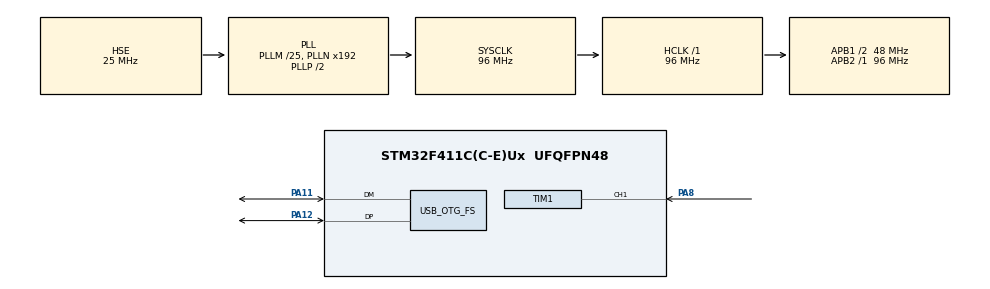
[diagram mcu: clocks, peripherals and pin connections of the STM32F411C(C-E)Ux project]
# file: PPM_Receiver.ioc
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Mcu.Family=STM32F4
Mcu.Name=STM32F411C(C-E)Ux
Mcu.Package=UFQFPN48
NVIC.OTG_FS_IRQn=true\:0\:0\:false\:false\:true\:false\:true\:true
NVIC.PriorityGroup=NVIC_PRIORITYGROUP_4
NVIC.TIM1_CC_IRQn=true\:0\:0\:false\:false\:true\:true\:true\:true
PA11.Mode=Device_Only
PA11.Signal=USB_OTG_FS_DM
PA12.Mode=Device_Only
PA12.Signal=USB_OTG_FS_DP
PA8.Signal=S_TIM1_CH1
PC14-OSC32_IN.Mode=LSE-External-Oscillator
PC14-OSC32_IN.Signal=RCC_OSC32_IN
PC15-OSC32_OUT.Mode=LSE-External-Oscillator
PC15-OSC32_OUT.Signal=RCC_OSC32_OUT
PH0\ -\ OSC_IN.Mode=HSE-External-Oscillator
PH0\ -\ OSC_IN.Signal=RCC_OSC_IN
PH1\ -\ OSC_OUT.Mode=HSE-External-Oscillator
PH1\ -\ OSC_OUT.Signal=RCC_OSC_OUT
ProjectManager.HeapSize=0x200
ProjectManager.StackSize=0x400
ProjectManager.TargetToolchain=Makefile
RCC.48MHZClocksFreq_Value=48000000
RCC.AHBFreq_Value=96000000
RCC.APB1CLKDivider=RCC_HCLK_DIV2
RCC.APB1Freq_Value=48000000
RCC.APB1TimFreq_Value=96000000
RCC.APB2Freq_Value=96000000
RCC.APB2TimFreq_Value=96000000
RCC.CortexFreq_Value=96000000
RCC.HCLKFreq_Value=96000000
RCC.HSE_VALUE=25000000
RCC.HSI_VALUE=16000000
RCC.PLLM=25
RCC.PLLSourceVirtual=RCC_PLLSOURCE_HSE
RCC.SYSCLKFreq_VALUE=96000000
RCC.SYSCLKSource=RCC_SYSCLKSOURCE_PLLCLK
RCC.VCOOutputFreq_Value=192000000
SH.S_TIM1_CH1.0=TIM1_CH1,Input_Capture1_from_TI1
TIM1.Channel-Input_Capture1_from_TI1=TIM_CHANNEL_1
TIM1.ICPolarity_CH1=TIM_INPUTCHANNELPOLARITY_FALLING
TIM1.Prescaler=96 - 1
USB_DEVICE.CLASS_NAME_FS=CDC
USB_DEVICE.VirtualMode=Cdc
USB_DEVICE.VirtualModeFS=Cdc_FS
USB_OTG_FS.VirtualMode=Device_Only
VP_TIM1_VS_ClockSourceINT.Mode=Internal
VP_USB_DEVICE_VS_USB_DEVICE_CDC_FS.Mode=CDC_FS
board=custom

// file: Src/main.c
/* USER CODE BEGIN Header */
/**
  ******************************************************************************
  * @file           : main.c
  * @brief          : Main program body
  ******************************************************************************
  * @attention
  *
  * Copyright (c) 2022 STMicroelectronics.
  * All rights reserved.
  *
  * This software is licensed under terms that can be found in the LICENSE file
  * in the root directory of this software component.
  * If no LICENSE file comes with this software, it is provided AS-IS.
  *
  ******************************************************************************
  */
/* USER CODE END Header */
#include "main.h"
#include "usb_device.h"

/* USER CODE BEGIN Includes */
#include "usbd_cdc_if.h"
#include "FS-IA10B_driver.h"

/* USER CODE END Includes */

TIM_HandleTypeDef htim1;

void SystemClock_Config(void);
static void MX_GPIO_Init(void);
static void MX_TIM1_Init(void);
/* USER CODE BEGIN PFP */
extern uint8_t CDC_Transmit_FS(uint8_t* Buf, uint16_t Len);
extern uint16_t fsia10b_channel_values[];

/* USER CODE END PFP */

/* USER CODE BEGIN 0 */

void HAL_TIM_IC_CaptureCallback(TIM_HandleTypeDef *htim){
    FSIA10B_INT(htim);
}

int _write(int file, char *ptr, int len)
{
    UNUSED(file);
    CDC_Transmit_FS((uint8_t*)ptr, len);
    return len;
}

/* USER CODE END 0 */

int main(void)
{

  /* MCU Configuration--------------------------------------------------------*/

  /* Reset of all peripherals, Initializes the Flash interface and the Systick. */
  HAL_Init();

  /* Configure the system clock */
  SystemClock_Config();

  /* Initialize all configured peripherals */
  MX_GPIO_Init();
  MX_TIM1_Init();
  MX_USB_DEVICE_Init();
  /* USER CODE BEGIN 2 */

  HAL_StatusTypeDef error = HAL_TIM_IC_Start_IT(&htim1, TIM_CHANNEL_1);

  /* USER CODE END 2 */

  /* Infinite loop */
    while (1)
    {

    /* USER CODE BEGIN 3 */
        printf("1 - %4d, 2 - %4d, 3 - %4d, 4 - %4d, 5 - %4d, 6 - %4d, 7 - %4d, 8 - %4d\n",
            fsia10b_channel_values[0], fsia10b_channel_values[1], fsia10b_channel_values[2], fsia10b_channel_values[3],
            fsia10b_channel_values[4], fsia10b_channel_values[5], fsia10b_channel_values[6], fsia10b_channel_values[7]);
        HAL_Delay(500);
    }
  /* USER CODE END 3 */
}

void SystemClock_Config(void)
{
  RCC_OscInitTypeDef RCC_OscInitStruct = {0};
  RCC_ClkInitTypeDef RCC_ClkInitStruct = {0};

  /** Configure the main internal regulator output voltage
  */
  __HAL_RCC_PWR_CLK_ENABLE();
  __HAL_PWR_VOLTAGESCALING_CONFIG(PWR_REGULATOR_VOLTAGE_SCALE1);

  /** Initializes the RCC Oscillators according to the specified parameters
  * in the RCC_OscInitTypeDef structure.
  */
  RCC_OscInitStruct.OscillatorType = RCC_OSCILLATORTYPE_HSE;
  RCC_OscInitStruct.HSEState = RCC_HSE_ON;
  RCC_OscInitStruct.PLL.PLLState = RCC_PLL_ON;
  RCC_OscInitStruct.PLL.PLLSource = RCC_PLLSOURCE_HSE;
  RCC_OscInitStruct.PLL.PLLM = 25;
  RCC_OscInitStruct.PLL.PLLN = 192;
  RCC_OscInitStruct.PLL.PLLP = RCC_PLLP_DIV2;
  RCC_OscInitStruct.PLL.PLLQ = 4;
  if (HAL_RCC_OscConfig(&RCC_OscInitStruct) != HAL_OK)
  {
    Error_Handler();
  }

  /** Initializes the CPU, AHB and APB buses clocks
  */
  RCC_ClkInitStruct.ClockType = RCC_CLOCKTYPE_HCLK|RCC_CLOCKTYPE_SYSCLK
                              |RCC_CLOCKTYPE_PCLK1|RCC_CLOCKTYPE_PCLK2;
  RCC_ClkInitStruct.SYSCLKSource = RCC_SYSCLKSOURCE_PLLCLK;
  RCC_ClkInitStruct.AHBCLKDivider = RCC_SYSCLK_DIV1;
  RCC_ClkInitStruct.APB1CLKDivider = RCC_HCLK_DIV2;
  RCC_ClkInitStruct.APB2CLKDivider = RCC_HCLK_DIV1;

  if (HAL_RCC_ClockConfig(&RCC_ClkInitStruct, FLASH_LATENCY_3) != HAL_OK)
  {
    Error_Handler();
  }
}

static void MX_TIM1_Init(void)
{

  TIM_ClockConfigTypeDef sClockSourceConfig = {0};
  TIM_MasterConfigTypeDef sMasterConfig = {0};
  TIM_IC_InitTypeDef sConfigIC = {0};

  htim1.Instance = TIM1;
  htim1.Init.Prescaler = 96 - 1;
  htim1.Init.CounterMode = TIM_COUNTERMODE_UP;
  htim1.Init.Period = 65535;
  htim1.Init.ClockDivision = TIM_CLOCKDIVISION_DIV1;
  htim1.Init.RepetitionCounter = 0;
  htim1.Init.AutoReloadPreload = TIM_AUTORELOAD_PRELOAD_DISABLE;
  if (HAL_TIM_Base_Init(&htim1) != HAL_OK)
  {
    Error_Handler();
  }
  sClockSourceConfig.ClockSource = TIM_CLOCKSOURCE_INTERNAL;
  if (HAL_TIM_ConfigClockSource(&htim1, &sClockSourceConfig) != HAL_OK)
  {
    Error_Handler();
  }
  if (HAL_TIM_IC_Init(&htim1) != HAL_OK)
  {
    Error_Handler();
  }
  sMasterConfig.MasterOutputTrigger = TIM_TRGO_RESET;
  sMasterConfig.MasterSlaveMode = TIM_MASTERSLAVEMODE_DISABLE;
  if (HAL_TIMEx_MasterConfigSynchronization(&htim1, &sMasterConfig) != HAL_OK)
  {
    Error_Handler();
  }
  sConfigIC.ICPolarity = TIM_INPUTCHANNELPOLARITY_FALLING;
  sConfigIC.ICSelection = TIM_ICSELECTION_DIRECTTI;
  sConfigIC.ICPrescaler = TIM_ICPSC_DIV1;
  sConfigIC.ICFilter = 0;
  if (HAL_TIM_IC_ConfigChannel(&htim1, &sConfigIC, TIM_CHANNEL_1) != HAL_OK)
  {
    Error_Handler();
  }

}

static void MX_GPIO_Init(void)
{

  /* GPIO Ports Clock Enable */
  __HAL_RCC_GPIOC_CLK_ENABLE();
  __HAL_RCC_GPIOH_CLK_ENABLE();
  __HAL_RCC_GPIOA_CLK_ENABLE();

}

void Error_Handler(void)
{
  __disable_irq();
  while (1)
  {
  }
}
